# LKS32MC08x register map
Vendor: Linko Ltd.; Series: LKS32MC08x; File version: 1.0
CPU: CM0 r1p0, little endian, MPU, no FPU, 3 interrupt priority bits
Registers are 32-bit, read-write, reset 0x0 unless marked. A register's access mark holds for its fields unless they carry their own. Offsets are from the block's base; [hi:lo] are bit positions; {n}, {i} and the like mark numbered series; 'fields as' and 'values as' point back to an identical list.

## ENCODER0 — ENCODER0 registers
Base 0x40011880
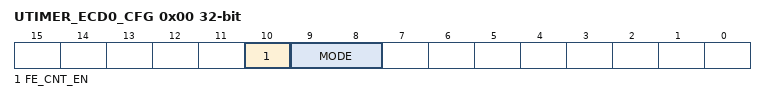
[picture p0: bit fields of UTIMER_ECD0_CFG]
0x00 UTIMER_ECD0_CFG — Encoder configuration
  [10] FE_CNT_EN — Count at falling edge enable
    0=Disabled (Will not count at falling edge); 1=Enabled (Will count at falling edge)
  [9:8] MODE — Encoder mode
0x04 UTIMER_ECD0_TH — Encoder counter threshold. Encoder will count from 0 to TH, then over again, or from TH down to 0 and over again
0x08 UTIMER_ECD0_CNT — Encoder current counter value

## ENCODER1 — ENCODER1 registers
Base 0x40011890
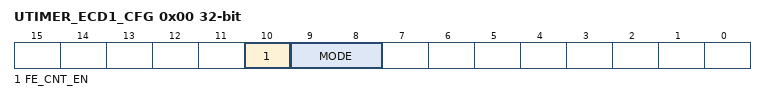
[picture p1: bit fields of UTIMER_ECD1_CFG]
0x00 UTIMER_ECD1_CFG — Encoder configuration
  [10] FE_CNT_EN — Count at falling edge enable
    0=Disabled (Will not count at falling edge); 1=Enabled (Will count at falling edge)
  [9:8] MODE — Encoder mode
0x04 UTIMER_ECD1_TH — Encoder counter threshold. Encoder will count from 0 to TH, then over again, or from TH down to 0 and over again
0x08 UTIMER_ECD1_CNT — Encoder current counter value

## UTIMER_CTRL — UTIMER_CTRL registers
Base 0x400118A0
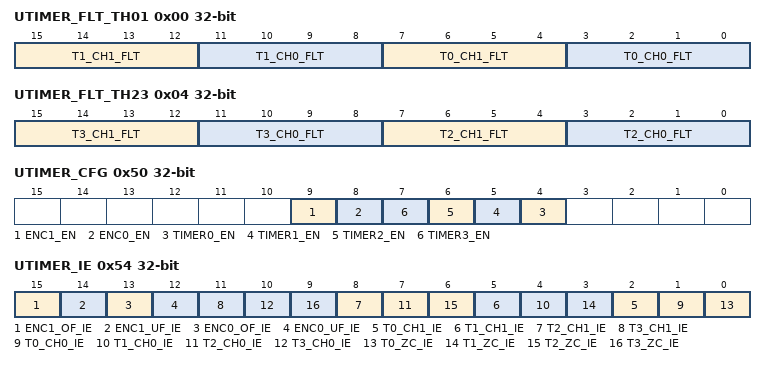
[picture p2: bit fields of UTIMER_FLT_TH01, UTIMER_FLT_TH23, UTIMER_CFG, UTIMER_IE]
0x00 UTIMER_FLT_TH01 — Timer channel filter bandwidth
  [15:12] T1_CH1_FLT — Timer1 channel1 filter bandwidth
  [11:8] T1_CH0_FLT — Timer1 channel0 filter bandwidth
  [7:4] T0_CH1_FLT — Timer0 channel1 filter bandwidth
  [3:0] T0_CH0_FLT — Timer0 channel0 filter bandwidth
0x04 UTIMER_FLT_TH23 — Timer channel filter bandwidth
  [15:12] T3_CH1_FLT — Timer3 channel1 filter bandwidth
  [11:8] T3_CH0_FLT — Timer3 channel0 filter bandwidth
  [7:4] T2_CH1_FLT — Timer2 channel1 filter bandwidth
  [3:0] T2_CH0_FLT — Timer2 channel0 filter bandwidth
0x50 UTIMER_CFG — Timer control
  [9] ENC1_EN — Encoder1 enable
    0=Disabled (Encoder disabled); 1=Enabled (Encoder enabled)
  [8] ENC0_EN — Encoder0 enable
    0=Disabled (Encoder disabled); 1=Enabled (Encoder enabled)
  [n+4] TIMER{n}_EN (n=0..3) — UTimer {n} enable
    0=Disabled (Timer disabled); 1=Enabled (Timer enabled)
0x54 UTIMER_IE — Timer interrupt enable
  [15] ENC1_OF_IE — Encoder1 overflow interrupt enable
    0=Disabled (Interrupt disabled); 1=Enabled (Interrupt enabled)
  [14] ENC1_UF_IE — Encoder1 underflow interrupt enable
    values as ENC1_OF_IE
  [13] ENC0_OF_IE — Encoder0 overflow interrupt enable
    values as ENC1_OF_IE
  [12] ENC0_UF_IE — Encoder0 underflow interrupt enable
    values as ENC1_OF_IE
  [3n+2] T{n}_CH1_IE (n=0..3) — Timer{n} channel1 interrupt enable
    values as ENC1_OF_IE
  [3n+1] T{n}_CH0_IE (n=0..3) — Timer{n} channel0 interrupt enable
    values as ENC1_OF_IE
  [3n] T{n}_ZC_IE (n=0..3) — Timer{n} zero crossing interrupt enable
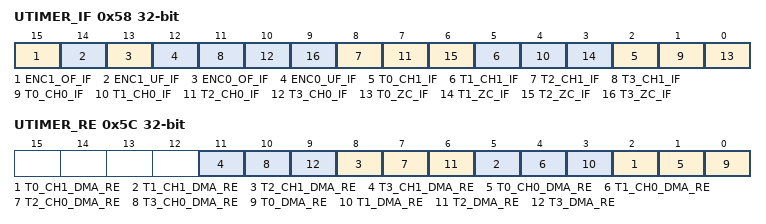
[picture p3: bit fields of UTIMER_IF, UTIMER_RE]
0x58 UTIMER_IF — Timer interrupt flag
  [15] ENC1_OF_IF — Encoder1 overflow interrupt flag
  [14] ENC1_UF_IF — Encoder1 underflow interrupt flag
  [13] ENC0_OF_IF — Encoder0 overflow interrupt flag
  [12] ENC0_UF_IF — Encoder0 underflow interrupt flag
  [3n+2] T{n}_CH1_IF (n=0..3) — Timer{n} channel1 interrupt flag
  [3n+1] T{n}_CH0_IF (n=0..3) — Timer{n} channel0 interrupt flag
  [3n] T{n}_ZC_IF (n=0..3) — Timer{n} zero crossing interrupt flag
0x5C UTIMER_RE — Timer DMA request enable
  [3n+2] T{n}_CH1_DMA_RE (n=0..3) — Timer{n} channel1 DMA request enable
  [3n+1] T{n}_CH0_DMA_RE (n=0..3) — Timer{n} channel0 DMA request enable
  [3n] T{n}_DMA_RE (n=0..3) — Timer{n} DMA request enable

## GPIO — GPIO registers
Base 0x40012000
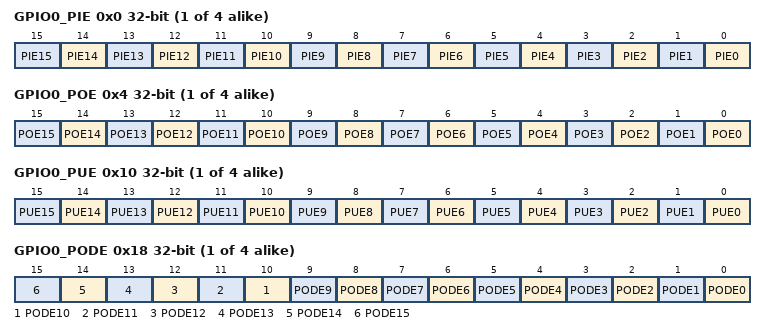
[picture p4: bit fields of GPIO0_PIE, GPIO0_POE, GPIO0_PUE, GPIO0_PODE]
{0x0+0x40*i} GPIO{i}_PIE (i=0..3) — GPIO{i} input enable
  [all] fields
    0=Disabled (input always read as 0); 1=Enabled (input enabled)
  [n] PIE{n} (n=0..15) — GPIO[{n}] input enable
{0x4+0x40*i} GPIO{i}_POE (i=0..3) — GPIO{i} output enable
  [all] fields
    0=Disabled (output disabled); 1=Enabled (output enabled)
  [n] POE{n} (n=0..15) — GPIO[{n}] output enable
{0x8+0x40*i} GPIO{i}_PDI (i=0..3) — GPIO{i} input data
{0xC+0x40*i} GPIO{i}_PDO (i=0..3) — GPIO{i} output data
{0x10+0x40*i} GPIO{i}_PUE (i=0..3) — GPIO{i} pull-up enable
  [all] fields
    0=Disabled (pull-up disabled); 1=Enabled (pull-up enabled)
  [n] PUE{n} (n=0..15) — GPIO[{n}] pull-up enable
{0x18+0x40*i} GPIO{i}_PODE (i=0..3) — GPIO{i} open drain enable
  [all] fields
    0=Disabled (open drain disabled); 1=Enabled (open drain enabled)
  [n] PODE{n} (n=0..15) — GPIO[{n}] open drain enable
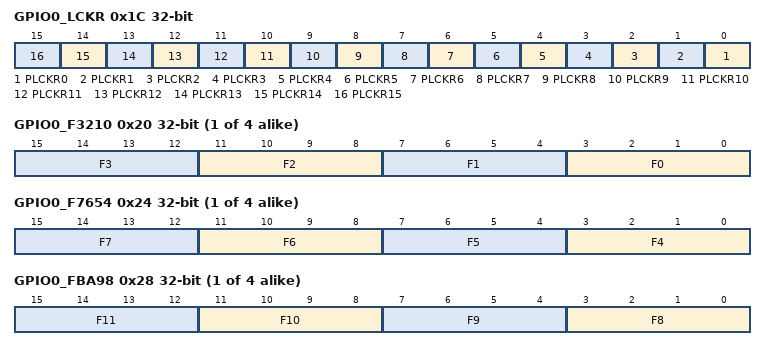
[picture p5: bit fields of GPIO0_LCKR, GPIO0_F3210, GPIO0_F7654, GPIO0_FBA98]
0x1C GPIO0_LCKR — GPIO0 configuration lock
  [all] fields
    0=Disabled (config unlocked); 1=Enabled (config locked)
  [n] PLCKR{n} (n=0..15) — GPIO[{n}] config lock
{0x20+0x40*i} GPIO{i}_F3210 (i=0..3) — GPIO{i}[3:0] function selection
  [4n+3:4n] F{n} (n=0..3) — GPIO[{n}] function selection
{0x24+0x40*i} GPIO{i}_F7654 (i=0..3) — GPIO{i}[7:4] function selection
  [4n-13:4n-16] F{n} (n=4..7) — GPIO[{n}] function selection
{0x28+0x40*i} GPIO{i}_FBA98 (i=0..3) — GPIO{i}[11:8] function selection
  [4n-29:4n-32] F{n} (n=8..11) — GPIO[{n}] function selection
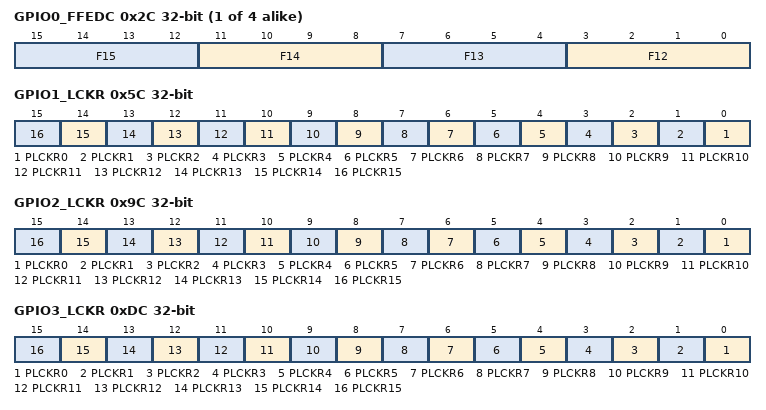
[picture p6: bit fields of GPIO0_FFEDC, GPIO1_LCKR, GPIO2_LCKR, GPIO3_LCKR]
{0x2C+0x40*i} GPIO{i}_FFEDC (i=0..3) — GPIO{i}[15:12] function selection
  [4n-45:4n-48] F{n} (n=12..15) — GPIO[{n-12}] function selection
0x5C GPIO1_LCKR — GPIO1 configuration lock
  fields as GPIO0_LCKR
0x9C GPIO2_LCKR — GPIO2 configuration lock
  [all] fields
    0=Unlocked (config unlocked); 1=Locked (config locked)
  [n] PLCKR{n} (n=0..15) — GPIO[{n}] config lock
0xDC GPIO3_LCKR — GPIO3 configuration lock
  fields as GPIO2_LCKR
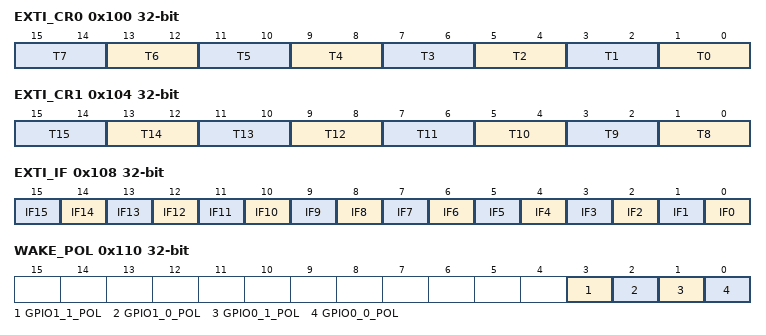
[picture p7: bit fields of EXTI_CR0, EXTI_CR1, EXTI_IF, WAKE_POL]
0x100 EXTI_CR0 — GPIO0[7:0] external interrupt trigger type
  [2n+1:2n] T{n} (n=0..7) — GPIO0[{n}] external interrupt trigger type
0x104 EXTI_CR1 — GPIO0[15:8] external interrupt trigger type
  [2n-15:2n-16] T{n} (n=8..15) — GPIO0[{n}] external interrupt trigger type
0x108 EXTI_IF — GPIO interrupt flag
  [n] IF{n} (n=0..15) — GPIO[{n}] interrupt flag
0x10C LCKR_PRT wo — GPIO lock protect, write 0x5AC4 to disable GPIO_LCKR protection, write any other value to enable GPIO_LCKR protection
0x110 WAKE_POL — GPIO wake-up polarity
  [all] fields
    0=LW (low level signal wake-up); 1=HW (high level signal wake-up)
  [3] GPIO1_1_POL — GPIO1[1] external wake-up signal polarity
  [2] GPIO1_0_POL — GPIO1[0] external wake-up signal polarity
  [1] GPIO0_1_POL — GPIO0[1] external wake-up signal polarity
  [0] GPIO0_0_POL — GPIO0[0] external wake-up signal polarity
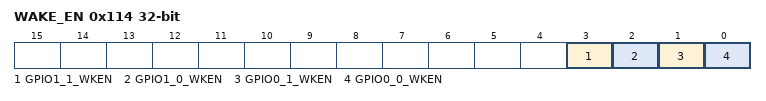
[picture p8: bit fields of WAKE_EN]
0x114 WAKE_EN — GPIO wake-up enable
  [all] fields
    0=Disabled (GPIO wake-up disabled); 1=Enabled (GPIO wake-up enabled)
  [3] GPIO1_1_WKEN — GPIO1[1] external wake-up enable
  [2] GPIO1_0_WKEN — GPIO1[0] external wake-up enable
  [1] GPIO0_1_WKEN — GPIO0[1] external wake-up enable
  [0] GPIO0_0_WKEN — GPIO0[0] external wake-up enable
